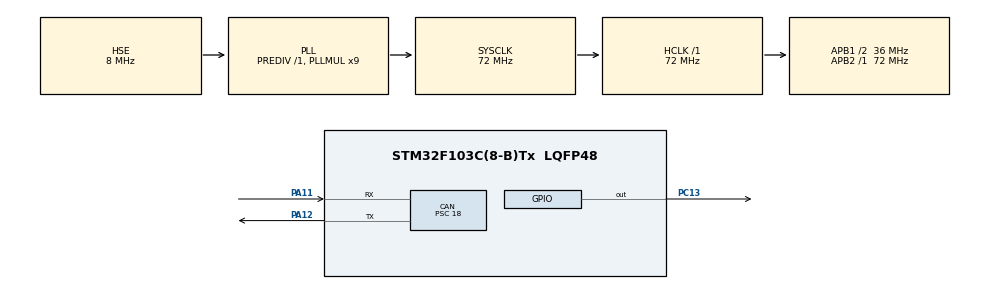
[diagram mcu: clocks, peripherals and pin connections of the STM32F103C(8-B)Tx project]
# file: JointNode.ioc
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CAN.ABOM=DISABLE
CAN.AWUM=DISABLE
CAN.BS1=CAN_BS1_13TQ
CAN.BS2=CAN_BS2_2TQ
CAN.CalculateBaudRate=125000
CAN.CalculateTimeBit=8000
CAN.CalculateTimeQuantum=500.0
CAN.NART=ENABLE
CAN.Prescaler=18
Mcu.Family=STM32F1
Mcu.Name=STM32F103C(8-B)Tx
Mcu.Package=LQFP48
NVIC.PriorityGroup=NVIC_PRIORITYGROUP_4
NVIC.USB_LP_CAN1_RX0_IRQn=true\:0\:0\:false\:false\:true\:true\:true\:true
PA11.Mode=CAN_Activate
PA11.Signal=CAN_RX
PA12.Mode=CAN_Activate
PA12.Signal=CAN_TX
PA13.Mode=Serial_Wire
PA13.Signal=SYS_JTMS-SWDIO
PA14.Mode=Serial_Wire
PA14.Signal=SYS_JTCK-SWCLK
PC13-TAMPER-RTC.Signal=GPIO_Output
PD0-OSC_IN.Mode=HSE-External-Oscillator
PD0-OSC_IN.Signal=RCC_OSC_IN
PD1-OSC_OUT.Mode=HSE-External-Oscillator
PD1-OSC_OUT.Signal=RCC_OSC_OUT
ProjectManager.HeapSize=0x200
ProjectManager.StackSize=0x400
ProjectManager.TargetToolchain=CMake
RCC.AHBFreq_Value=72000000
RCC.APB1CLKDivider=RCC_HCLK_DIV2
RCC.APB1Freq_Value=36000000
RCC.APB1TimFreq_Value=72000000
RCC.APB2Freq_Value=72000000
RCC.APB2TimFreq_Value=72000000
RCC.HCLKFreq_Value=72000000
RCC.PLLMUL=RCC_PLL_MUL9
RCC.PLLSourceVirtual=RCC_PLLSOURCE_HSE
RCC.SYSCLKFreq_VALUE=72000000
RCC.SYSCLKSource=RCC_SYSCLKSOURCE_PLLCLK
RCC.USBFreq_Value=72000000
board=custom

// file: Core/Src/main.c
/* USER CODE BEGIN Header */
/**
  ******************************************************************************
  * @file           : main.c
  * @brief          : Main program body
  ******************************************************************************
  * @attention
  *
  * Copyright (c) 2026 STMicroelectronics.
  * All rights reserved.
  *
  * This software is licensed under terms that can be found in the LICENSE file
  * in the root directory of this software component.
  * If no LICENSE file comes with this software, it is provided AS-IS.
  *
  ******************************************************************************
  */
/* USER CODE END Header */
#include "main.h"
#include "can.h"
#include "gpio.h"

void SystemClock_Config(void);

int main(void)
{

  /* MCU Configuration--------------------------------------------------------*/

  /* Reset of all peripherals, Initializes the Flash interface and the Systick. */
  HAL_Init();

  /* Configure the system clock */
  SystemClock_Config();

  /* Initialize all configured peripherals */
  MX_GPIO_Init();
  MX_CAN_Init();
  /* USER CODE BEGIN 2 */

  //配置过滤器（接收准备)
  CAN_FilterTypeDef  sFilterConfig;   //创建过滤器配置结构体的变量

  sFilterConfig.FilterActivation = ENABLE;    //开始配置过滤器，对结构体内各参数赋值（当前，接收所有ID）
  sFilterConfig.FilterMode = CAN_FILTERMODE_IDMASK;
  sFilterConfig.FilterScale = CAN_FILTERSCALE_32BIT;
  sFilterConfig.FilterIdHigh = 0x0000;
  sFilterConfig.FilterIdLow = 0x0000;
  sFilterConfig.FilterMaskIdHigh = 0x0000;
  sFilterConfig.FilterMaskIdLow = 0x0000;
  sFilterConfig.FilterFIFOAssignment = CAN_RX_FIFO0;
  sFilterConfig.FilterBank = 0;
  sFilterConfig.SlaveStartFilterBank = 0;

  //使用函数将配置结构体应用
  if(HAL_CAN_ConfigFilter(&hcan,&sFilterConfig)!=HAL_OK)
  {
    Error_Handler();    //错误跳转
  }

  //启动CAN外设
  if (HAL_CAN_Start(&hcan)!=HAL_OK)
  {
    Error_Handler();
  }

  //使能CAN接收中断
  if(HAL_CAN_ActivateNotification(&hcan,CAN_IT_RX_FIFO0_MSG_PENDING)!=HAL_OK)
  {
    Error_Handler();
  }

  /* USER CODE END 2 */

  /* Infinite loop */
  while (1)
  {

    /* USER CODE BEGIN 3 */

    HAL_GPIO_WritePin(GPIOC,GPIO_PIN_13,GPIO_PIN_RESET);

      HAL_Delay(500);

  }
  /* USER CODE END 3 */
}

void SystemClock_Config(void)
{
  RCC_OscInitTypeDef RCC_OscInitStruct = {0};
  RCC_ClkInitTypeDef RCC_ClkInitStruct = {0};

  /** Initializes the RCC Oscillators according to the specified parameters
  * in the RCC_OscInitTypeDef structure.
  */
  RCC_OscInitStruct.OscillatorType = RCC_OSCILLATORTYPE_HSE;
  RCC_OscInitStruct.HSEState = RCC_HSE_ON;
  RCC_OscInitStruct.HSEPredivValue = RCC_HSE_PREDIV_DIV1;
  RCC_OscInitStruct.HSIState = RCC_HSI_ON;
  RCC_OscInitStruct.PLL.PLLState = RCC_PLL_ON;
  RCC_OscInitStruct.PLL.PLLSource = RCC_PLLSOURCE_HSE;
  RCC_OscInitStruct.PLL.PLLMUL = RCC_PLL_MUL9;
  if (HAL_RCC_OscConfig(&RCC_OscInitStruct) != HAL_OK)
  {
    Error_Handler();
  }

  /** Initializes the CPU, AHB and APB buses clocks
  */
  RCC_ClkInitStruct.ClockType = RCC_CLOCKTYPE_HCLK|RCC_CLOCKTYPE_SYSCLK
                              |RCC_CLOCKTYPE_PCLK1|RCC_CLOCKTYPE_PCLK2;
  RCC_ClkInitStruct.SYSCLKSource = RCC_SYSCLKSOURCE_PLLCLK;
  RCC_ClkInitStruct.AHBCLKDivider = RCC_SYSCLK_DIV1;
  RCC_ClkInitStruct.APB1CLKDivider = RCC_HCLK_DIV2;
  RCC_ClkInitStruct.APB2CLKDivider = RCC_HCLK_DIV1;

  if (HAL_RCC_ClockConfig(&RCC_ClkInitStruct, FLASH_LATENCY_2) != HAL_OK)
  {
    Error_Handler();
  }
}

/* USER CODE BEGIN 4 */

//重新定义接收中断回调函数
CAN_RxHeaderTypeDef RxHeader;
uint8_t RxData[8];

volatile uint32_t rx_count = 0;

void HAL_CAN_RxFifo0MsgPendingCallback(CAN_HandleTypeDef *hcan)
{
  HAL_CAN_GetRxMessage(
      hcan,
      CAN_RX_FIFO0,
      &RxHeader,
      RxData
  );

  rx_count++;

  HAL_GPIO_TogglePin(GPIOC, GPIO_PIN_13);
}

/* USER CODE END 4 */

void Error_Handler(void)
{
  __disable_irq();
  while (1)
  {
  }
}
